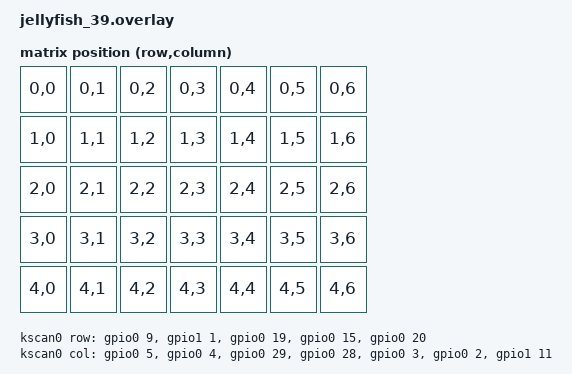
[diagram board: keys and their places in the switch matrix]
// This file was generated from a template. Edit it to match your keyboard.
// See https://zmk.dev/docs/development/hardware-integration/new-shield for more
// instructions.

#include <dt-bindings/zmk/matrix_transform.h>

/ {
    chosen {
        zmk,kscan = &kscan0;
        zmk,matrix-transform = &default_transform;
    };

    default_transform: keymap_transform0 {
        compatible = "zmk,matrix-transform";
        columns = <7>;
        rows = <5>;
        map = <
            RC(0,0) RC(0,1) RC(0,2) RC(0,3) RC(0,4) RC(0,5) RC(0,6)
            RC(1,0) RC(1,1) RC(1,2) RC(1,3) RC(1,4) RC(1,5) RC(1,6)
            RC(2,0) RC(2,1) RC(2,2) RC(2,3) RC(2,4) RC(2,5) RC(2,6)
            RC(3,0) RC(3,1) RC(3,2) RC(3,3) RC(3,4) RC(3,5) RC(3,6)
            RC(4,0) RC(4,1) RC(4,2) RC(4,3) RC(4,4) RC(4,5) RC(4,6)
        >;
    };

    kscan0: kscan {
        compatible = "zmk,kscan-gpio-matrix";
        diode-direction = "col2row";

        // 画像の「Pin No.」列に基づいた正しい指定
        row-gpios
            = <&gpio0 9  (GPIO_ACTIVE_LOW | GPIO_PULL_UP)> // D14 (P0.09)
            , <&gpio1 1  (GPIO_ACTIVE_LOW | GPIO_PULL_UP)> // D13 (P1.01)
            , <&gpio0 19 (GPIO_ACTIVE_LOW | GPIO_PULL_UP)> // D12 (P0.19)
            , <&gpio0 15 (GPIO_ACTIVE_LOW | GPIO_PULL_UP)> // D11 (P0.15)
            , <&gpio0 20 (GPIO_ACTIVE_LOW | GPIO_PULL_UP)> // D10 (P0.20)
            ;

        col-gpios
            = <&gpio0 5  GPIO_ACTIVE_LOW> // D5 (P0.05)
            , <&gpio0 4  GPIO_ACTIVE_LOW> // D4 (P0.04)
            , <&gpio0 29 GPIO_ACTIVE_LOW> // D3 (P0.29)
            , <&gpio0 28 GPIO_ACTIVE_LOW> // D2 (P0.28)
            , <&gpio0 3  GPIO_ACTIVE_LOW> // D1 (P0.03)
            , <&gpio0 2  GPIO_ACTIVE_LOW> // D0 (P0.02)
            , <&gpio1 11 GPIO_ACTIVE_LOW> // D6 (P1.11)
            ;
    };
};

&led0 { status = "disabled"; };
&led1 { status = "disabled"; };
&led2 { status = "disabled"; };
